# HC32K118 register map
File version: 1.0
CPU: CM0+ r0p1, little endian, no MPU, no FPU, 2 interrupt priority bits
Registers are 32-bit, read-write, reset 0x0 unless marked. A register's access mark holds for its fields unless they carry their own. Offsets are from the block's base; [hi:lo] are bit positions; {n}, {i} and the like mark numbered series; 'fields as' and 'values as' point back to an identical list.

## EMB
Base 0x40006C00
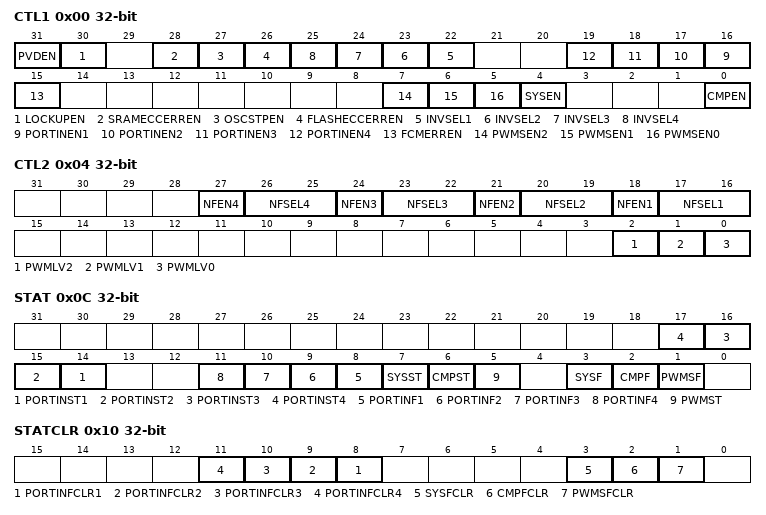
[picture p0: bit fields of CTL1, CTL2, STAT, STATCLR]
0x00 CTL1
  [31] PVDEN, [30] LOCKUPEN, [28] SRAMECCERREN, [27] OSCSTPEN, [26] FLASHECCERREN, [n+21] INVSEL{n} (n=1..4), [n+15] PORTINEN{n} (n=1..4), [15] FCMERREN, [7] PWMSEN2, [6] PWMSEN1, [5] PWMSEN0, [4] SYSEN, [0] CMPEN
0x04 CTL2
  [3n+15] NFEN{n} (n=1..4), [3n+14:3n+13] NFSEL{n} (n=1..4), [2] PWMLV2, [1] PWMLV1, [0] PWMLV0
0x08 SOE
  [0] SOE
0x0C STAT ro
  [n+13] PORTINST{n} (n=1..4), [n+7] PORTINF{n} (n=1..4), [7] SYSST, [6] CMPST, [5] PWMST, [3] SYSF, [2] CMPF, [1] PWMSF
0x10 STATCLR wo
  [n+7] PORTINFCLR{n} (n=1..4), [3] SYSFCLR, [2] CMPFCLR, [1] PWMSFCLR
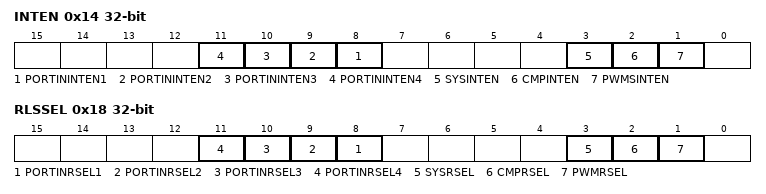
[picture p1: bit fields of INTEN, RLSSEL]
0x14 INTEN
  [n+7] PORTININTEN{n} (n=1..4), [3] SYSINTEN, [2] CMPINTEN, [1] PWMSINTEN
0x18 RLSSEL
  [n+7] PORTINRSEL{n} (n=1..4), [3] SYSRSEL, [2] CMPRSEL, [1] PWMRSEL

## FCM
Base 0x40005400
0x00 LVR
  [15:0] LVR
0x04 UVR
  [15:0] UVR
0x08 CNTR ro
  [15:0] CNTR
0x0C STR
  [0] START
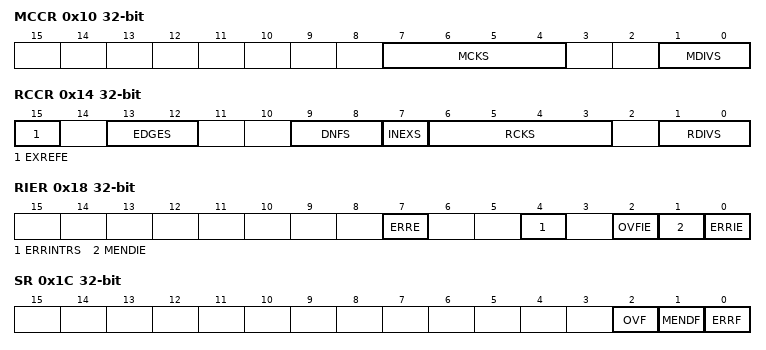
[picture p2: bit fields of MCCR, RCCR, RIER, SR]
0x10 MCCR
  [7:4] MCKS, [1:0] MDIVS
0x14 RCCR
  [15] EXREFE, [13:12] EDGES, [9:8] DNFS, [7] INEXS, [6:3] RCKS, [1:0] RDIVS
0x18 RIER
  [7] ERRE, [4] ERRINTRS, [2] OVFIE, [1] MENDIE, [0] ERRIE
0x1C SR ro
  [2] OVF, [1] MENDF, [0] ERRF
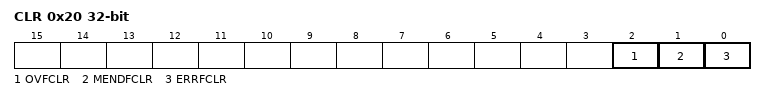
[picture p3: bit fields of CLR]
0x20 CLR wo
  [2] OVFCLR, [1] MENDFCLR, [0] ERRFCLR

## GPIO
Base 0x40013800
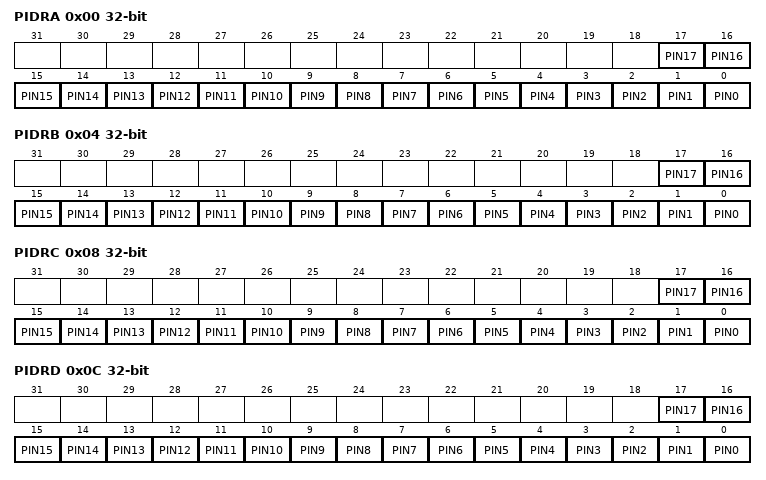
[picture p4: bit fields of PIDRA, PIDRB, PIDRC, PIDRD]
0x00 PIDRA ro (reset mask 0x3CFF)
  [n] PIN{n} (n=0..17)
0x04 PIDRB ro (reset mask 0x3CFF)
  [n] PIN{n} (n=0..17)
0x08 PIDRC ro (reset mask 0x3CFF)
  [n] PIN{n} (n=0..17)
0x0C PIDRD ro (reset mask 0x3CFF)
  [n] PIN{n} (n=0..17)
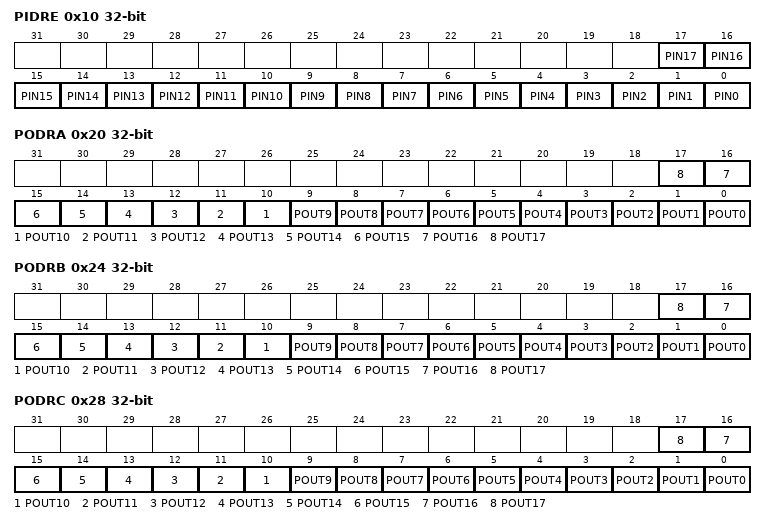
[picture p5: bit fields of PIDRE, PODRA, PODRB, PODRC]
0x10 PIDRE ro (reset mask 0x3CFF)
  [n] PIN{n} (n=0..17)
0x20 PODRA (reset mask 0x3CFF)
  [n] POUT{n} (n=0..17)
0x24 PODRB (reset mask 0x3CFF)
  [n] POUT{n} (n=0..17)
0x28 PODRC (reset mask 0x3CFF)
  [n] POUT{n} (n=0..17)
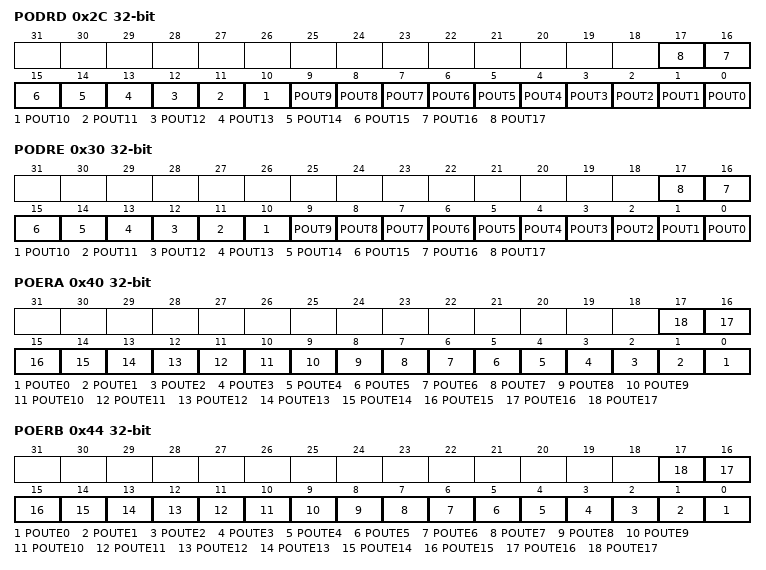
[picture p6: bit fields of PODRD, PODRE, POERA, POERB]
0x2C PODRD (reset mask 0x3CFF)
  [n] POUT{n} (n=0..17)
0x30 PODRE (reset mask 0x3CFF)
  [n] POUT{n} (n=0..17)
0x40 POERA (reset mask 0x3CFF)
  [n] POUTE{n} (n=0..17)
0x44 POERB (reset mask 0x3CFF)
  [n] POUTE{n} (n=0..17)
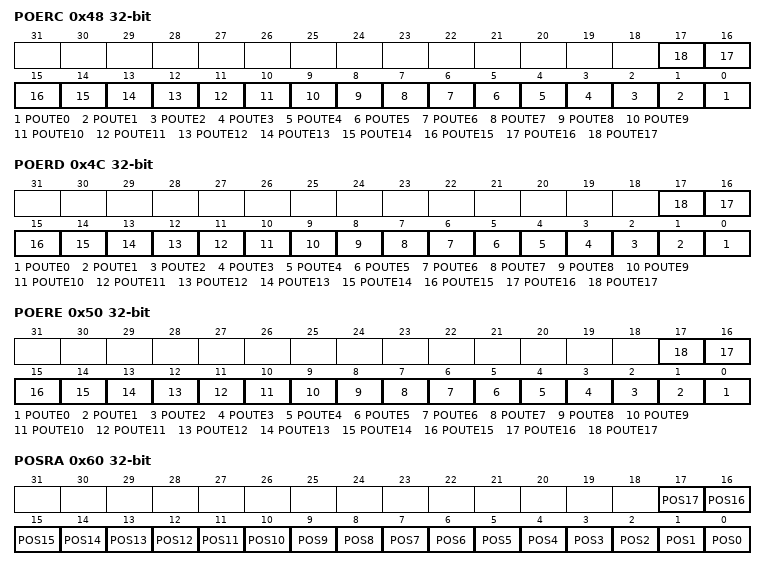
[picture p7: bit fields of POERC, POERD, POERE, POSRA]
0x48 POERC (reset mask 0x3CFF)
  [n] POUTE{n} (n=0..17)
0x4C POERD (reset mask 0x3CFF)
  [n] POUTE{n} (n=0..17)
0x50 POERE (reset mask 0x3CFF)
  [n] POUTE{n} (n=0..17)
0x60 POSRA (reset mask 0x3CFF)
  [n] POS{n} (n=0..17)
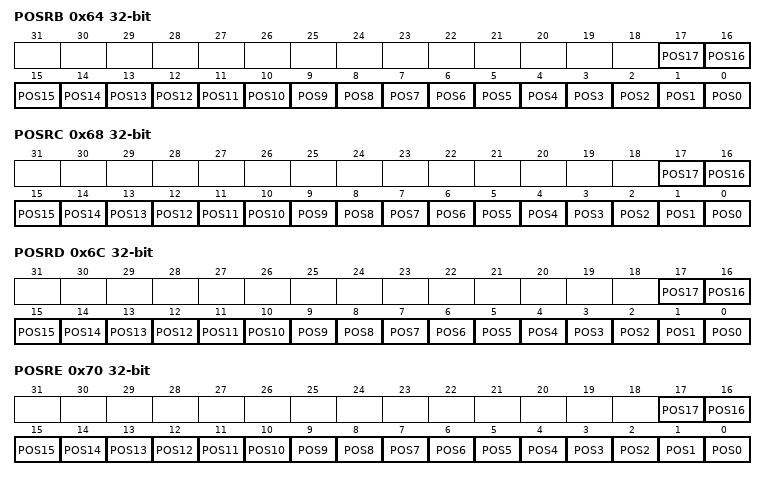
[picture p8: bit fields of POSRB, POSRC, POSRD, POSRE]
0x64 POSRB (reset mask 0x3CFF)
  [n] POS{n} (n=0..17)
0x68 POSRC (reset mask 0x3CFF)
  [n] POS{n} (n=0..17)
0x6C POSRD (reset mask 0x3CFF)
  [n] POS{n} (n=0..17)
0x70 POSRE (reset mask 0x3CFF)
  [n] POS{n} (n=0..17)
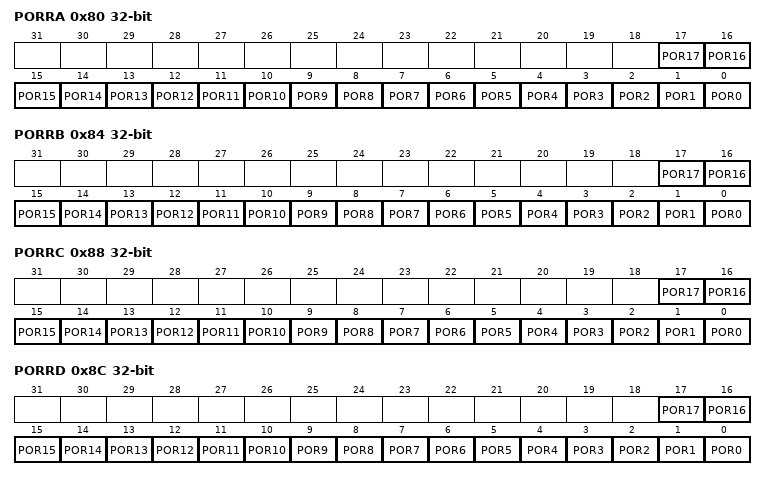
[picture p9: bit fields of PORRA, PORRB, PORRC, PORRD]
0x80 PORRA (reset mask 0x3CFF)
  [n] POR{n} (n=0..17)
0x84 PORRB (reset mask 0x3CFF)
  [n] POR{n} (n=0..17)
0x88 PORRC (reset mask 0x3CFF)
  [n] POR{n} (n=0..17)
0x8C PORRD (reset mask 0x3CFF)
  [n] POR{n} (n=0..17)
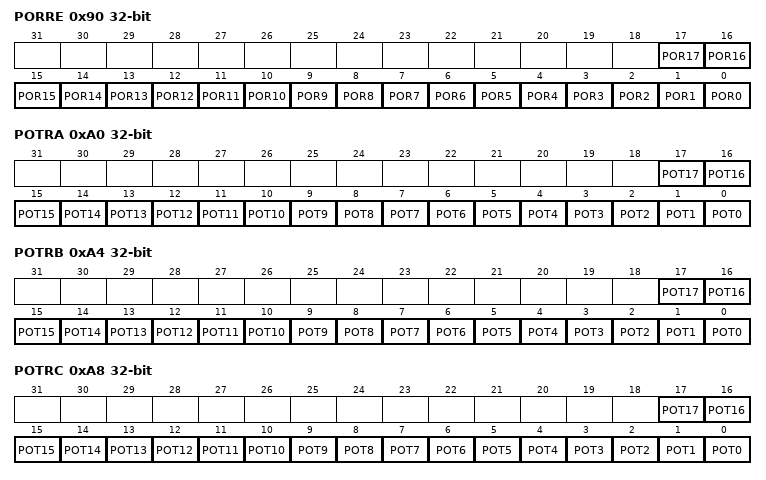
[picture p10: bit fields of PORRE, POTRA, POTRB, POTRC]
0x90 PORRE (reset mask 0x3CFF)
  [n] POR{n} (n=0..17)
0xA0 POTRA (reset mask 0x3CFF)
  [n] POT{n} (n=0..17)
0xA4 POTRB (reset mask 0x3CFF)
  [n] POT{n} (n=0..17)
0xA8 POTRC (reset mask 0x3CFF)
  [n] POT{n} (n=0..17)
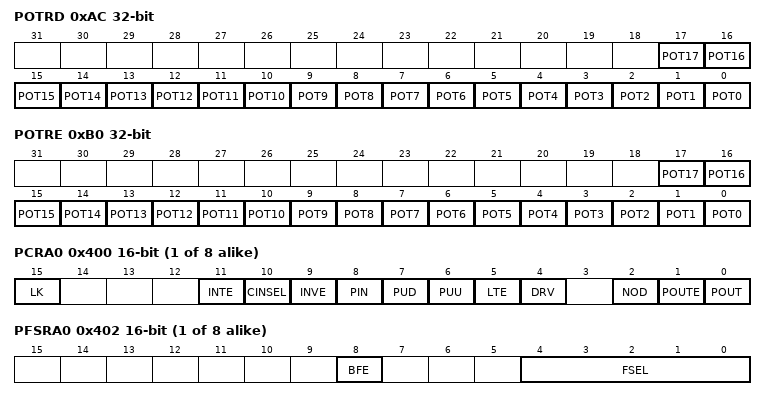
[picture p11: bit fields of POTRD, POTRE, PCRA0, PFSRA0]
0xAC POTRD (reset mask 0x3CFF)
  [n] POT{n} (n=0..17)
0xB0 POTRE (reset mask 0x3CFF)
  [n] POT{n} (n=0..17)
{0x400+4i} PCRA{i} 16-bit (i=0..7)
  [15] LK, [11] INTE, [10] CINSEL, [9] INVE, [8] PIN ro, [7] PUD, [6] PUU, [5] LTE, [4] DRV, [2] NOD, [1] POUTE, [0] POUT
{0x402+4i} PFSRA{i} 16-bit (i=0..7)
  [8] BFE, [4:0] FSEL
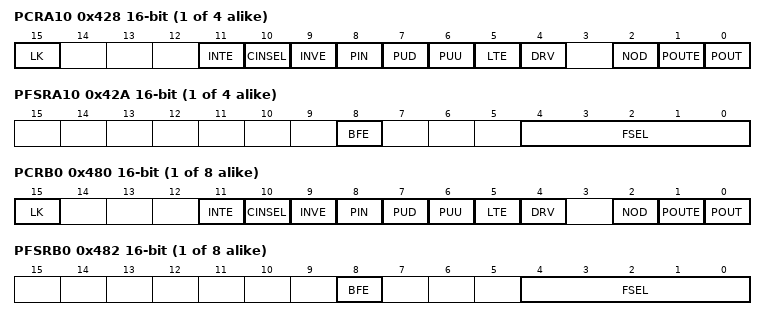
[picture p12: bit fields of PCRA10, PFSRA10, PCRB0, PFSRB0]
{0x400+4i} PCRA{i} 16-bit (i=10..13)
  fields as PCRA0
{0x402+4i} PFSRA{i} 16-bit (i=10..13)
  [8] BFE, [4:0] FSEL
{0x480+4i} PCRB{i} 16-bit (i=0..7)
  fields as PCRA0
{0x482+4i} PFSRB{i} 16-bit (i=0..7)
  [8] BFE, [4:0] FSEL
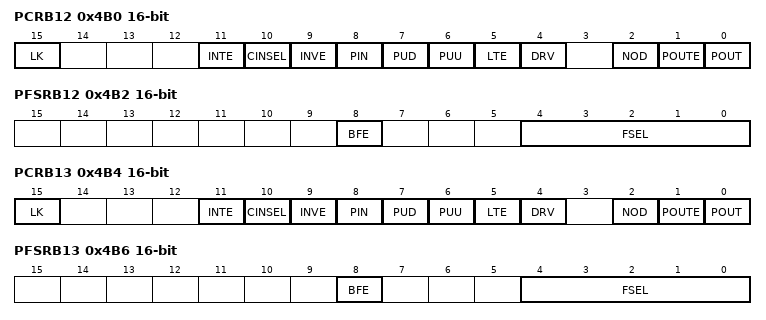
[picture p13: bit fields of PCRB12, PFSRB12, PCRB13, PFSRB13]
0x4B0 PCRB12 16-bit
  fields as PCRA0
0x4B2 PFSRB12 16-bit
  [8] BFE, [4:0] FSEL
0x4B4 PCRB13 16-bit
  fields as PCRA0
0x4B6 PFSRB13 16-bit
  [8] BFE, [4:0] FSEL
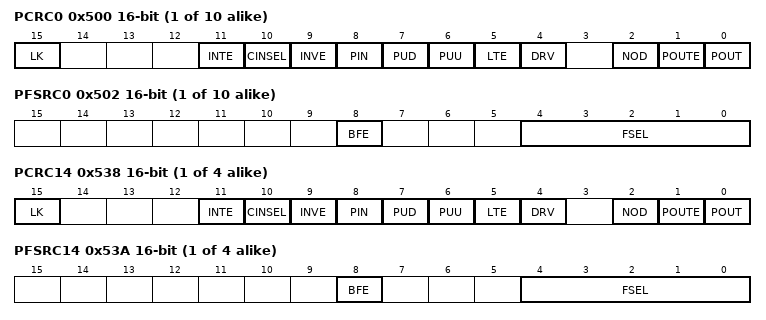
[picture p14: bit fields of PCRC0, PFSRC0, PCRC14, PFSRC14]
{0x500+4i} PCRC{i} 16-bit (i=0..9)
  fields as PCRA0
{0x502+4i} PFSRC{i} 16-bit (i=0..9)
  [8] BFE, [4:0] FSEL
{0x500+4i} PCRC{i} 16-bit (i=14..17)
  fields as PCRA0
{0x502+4i} PFSRC{i} 16-bit (i=14..17)
  [8] BFE, [4:0] FSEL
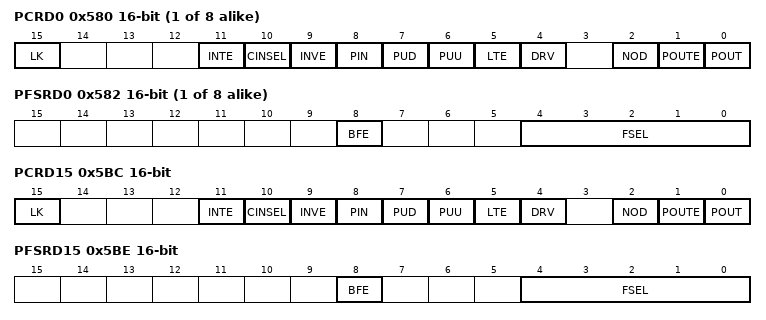
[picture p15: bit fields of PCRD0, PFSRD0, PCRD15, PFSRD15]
{0x580+4i} PCRD{i} 16-bit (i=0..7)
  fields as PCRA0
{0x582+4i} PFSRD{i} 16-bit (i=0..7)
  [8] BFE, [4:0] FSEL
0x5BC PCRD15 16-bit
  fields as PCRA0
0x5BE PFSRD15 16-bit
  [8] BFE, [4:0] FSEL
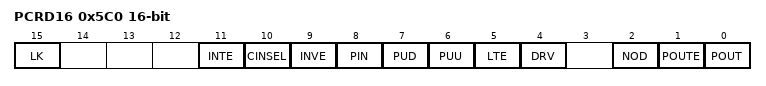
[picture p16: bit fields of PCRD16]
0x5C0 PCRD16 16-bit
  fields as PCRA0
0x5C2 PFSRD16 16-bit
  [8] BFE, [4:0] FSEL
{0x600+4i} PCRE{i} 16-bit (i=0..11)
  fields as PCRA0
{0x602+4i} PFSRE{i} 16-bit (i=0..11)
  [8] BFE, [4:0] FSEL
0x700 PSPCR 16-bit reset 0x3
  [8] NRSTOUTEN, [1:0] SPFE
0x704 PCCR 16-bit reset 0x4000
  [15:14] RDWT, [3:0] BFSEL
0x708 PINAER
  [4:0] PINAE
0x70C PWPR 16-bit
  [15:8] WP wo, [0] WE
